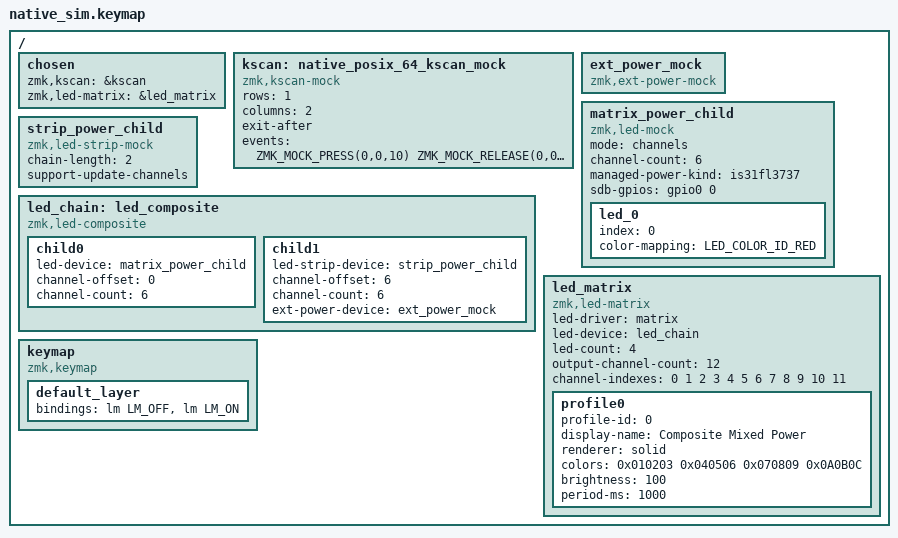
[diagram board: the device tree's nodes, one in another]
#include <behaviors.dtsi>
#include <dt-bindings/led/led.h>
#include <dt-bindings/zmk/kscan_mock.h>
#include <dt-bindings/zmk/led_matrix.h>

/ {
    chosen {
        zmk,kscan = &kscan;
        zmk,led-matrix = &led_matrix;
    };

    kscan: native_posix_64_kscan_mock {
        compatible = "zmk,kscan-mock";

        rows = <1>;
        columns = <2>;
        exit-after;
        events = <
            ZMK_MOCK_PRESS(0,0,10)
            ZMK_MOCK_RELEASE(0,0,10)
            ZMK_MOCK_PRESS(0,1,10)
            ZMK_MOCK_RELEASE(0,1,10)
        >;
    };

    ext_power_mock: ext_power_mock {
        compatible = "zmk,ext-power-mock";
    };

    matrix_power_child: matrix_power_child {
        compatible = "zmk,led-mock";
        mode = "channels";
        channel-count = <6>;
        managed-power-kind = "is31fl3737";
        sdb-gpios = <&gpio0 0 GPIO_ACTIVE_HIGH>;

        led_0 {
            index = <0>;
            color-mapping = <LED_COLOR_ID_RED>;
        };
    };

    strip_power_child: strip_power_child {
        compatible = "zmk,led-strip-mock";
        chain-length = <2>;
        support-update-channels;
    };

    led_chain: led_composite {
        compatible = "zmk,led-composite";

        child0 {
            led-device = <&matrix_power_child>;
            channel-offset = <0>;
            channel-count = <6>;
        };

        child1 {
            led-strip-device = <&strip_power_child>;
            channel-offset = <6>;
            channel-count = <6>;
            ext-power-device = <&ext_power_mock>;
        };
    };

    led_matrix: led_matrix {
        compatible = "zmk,led-matrix";
        led-driver = "matrix";
        led-device = <&led_chain>;
        led-count = <4>;
        output-channel-count = <12>;
        channel-indexes = <
            0 1 2
            3 4 5
            6 7 8
            9 10 11
        >;

        profile0 {
            profile-id = <0>;
            display-name = "Composite Mixed Power";
            renderer = "solid";
            colors = <0x010203 0x040506 0x070809 0x0A0B0C>;
            brightness = <100>;
            period-ms = <1000>;
        };
    };

    keymap {
        compatible = "zmk,keymap";

        default_layer {
            bindings = <
                &lm LM_OFF
                &lm LM_ON
            >;
        };
    };
};
